# STM32_UART register map
File version: 1.0
Universal Asynchronous Receiver Transmitter Register Map
Registers are 32-bit, read-write, reset 0x0 unless marked. A register's access mark holds for its fields unless they carry their own. Offsets are from the block's base; lines under a group give offsets from that group; [hi:lo] are bit positions; {n}, {i} and the like mark numbered series; 'fields as' and 'values as' point back to an identical list; <NAME> marks a mode.

## Memory map
0x40004000 UART0 size 0x1000 — UART Peripheral Controller

## UART0 — UART Peripheral Controller
Base 0x40004000
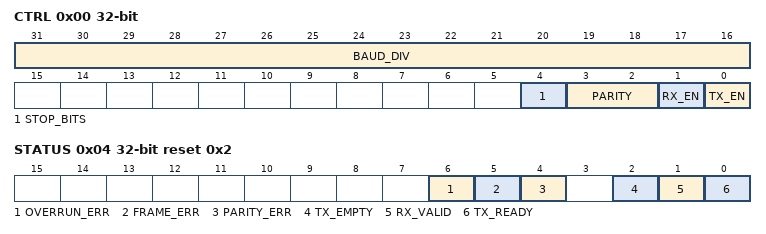
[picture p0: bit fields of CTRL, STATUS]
0x00 CTRL — Control Register
  [31:16] BAUD_DIV — Baud Rate Divisor
  [4] STOP_BITS — Stop Bits: 0=1 bit, 1=2 bits
  [3:2] PARITY — Parity Mode: 0=None, 1=Odd, 2=Even
  [1] RX_EN — Receiver Enable
  [0] TX_EN — Transmitter Enable
0x04 STATUS reset 0x2 — Status & Interrupt Flag Register
  [6] OVERRUN_ERR — Overrun Error Detected (Write 1 to clear)
  [5] FRAME_ERR — Framing Error Detected (Write 1 to clear)
  [4] PARITY_ERR — Parity Error Detected (Write 1 to clear)
  [2] TX_EMPTY ro — Transmitter Shift Register Empty
  [1] RX_VALID ro — Receiver FIFO Has Data
  [0] TX_READY ro — Transmitter Ready for Data
0x08 DATA — Transmit & Receive Data Buffer
  [7:0] BYTE — UART Data Byte
